# S1C31D50 register map
Vendor: Epson; Series: S1C31D50; File version: 1.00
CPU: CM0PLUS r0p1, little endian, MPU, no FPU, VTOR, 2 interrupt priority bits
Registers are 16-bit, read-write, reset 0x0 unless marked. A register's access mark holds for its fields unless they carry their own. Offsets are from the block's base; [hi:lo] are bit positions; {n}, {i} and the like mark numbered series; 'fields as' and 'values as' point back to an identical list.

## SDAC_0 — SOUND DAC
Base 0x00200860
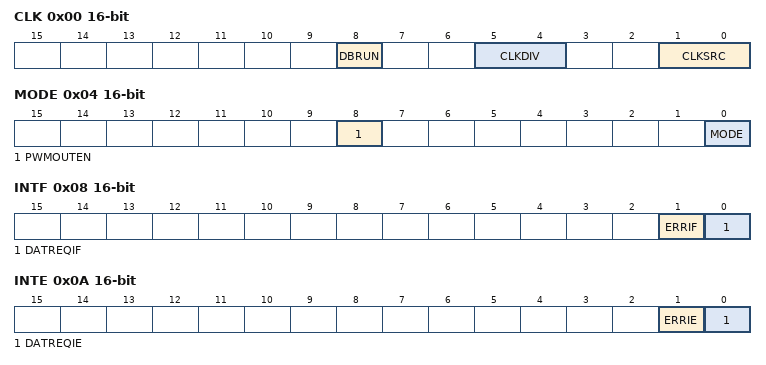
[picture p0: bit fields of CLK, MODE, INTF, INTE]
0x00 CLK — Clock Control Register
  [8] DBRUN — RUN
    0=STOP (Timer is stopped and does not operate); 1=RUN (Timer is started and operates)
  [5:4] CLKDIV — Clock division ratio
  [1:0] CLKSRC — Clock source select
    3=EXOSC (External OSC); 2=OSC3; 0=IOSC
0x02 CTL — SDAC Control Register
  [0] SDACEN — Enable SDAC operation
    1=ENABLE (SDAC Enable); 0=DISABLE (SDAC Disable)
0x04 MODE — SDAC mode select Register
  [8] PWMOUTEN — Enable PWM Output
    1=ENABLE (PWM Output Enable); 0=DISABLE (PWM Output Diable)
  [0] MODE — SDAC mode select
    1=BUZZ (Buzz mode); 0=STANDARD (Standard mode)
0x06 DAT — SDAC Data Register
  [9:0] DAT — SDAC Data
0x08 INTF — Interrupt Flag Register
  [1] ERRIF write-1-clears — ERROR occured interrupt flag
    0=NOT_OCCURED (No cause of interrupt occurred); 1=OCCURED (Cause of interrupt occurred)
  [0] DATREQIF write-1-clears — SDAC DATA request interrupt flag
    values as ERRIF
0x0A INTE — Interrupt Enable Register
  [1] ERRIE — ERROR occued interrupt enable
    0=DISABLE; 1=ENABLE
  [0] DATREQIE — SDAC DATA request interrupt enable
    0=DISABLE; 1=ENABLE
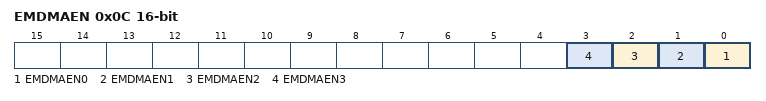
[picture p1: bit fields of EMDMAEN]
0x0C EMDMAEN — SDAC Buffer Empty DMA Request Enable Register
  [all] fields
    0=DISABLE; 1=ENABLE
  [n] EMDMAEN{n} (n=0..3) — Buffer Empty DMA ch{n} request enable

## HWPROC — HW Processor
Base 0x002008A0
0x02 CTL — HW Processor Control Register
  [0] HWPEN — HW Processor Enable
    0=DISABLE (SOUND Disabled (clock is stopped)); 1=ENABLE (SOUND Enabled (clock is supplied))
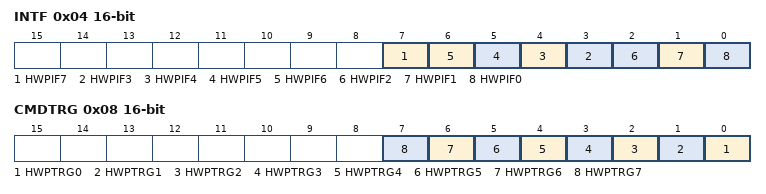
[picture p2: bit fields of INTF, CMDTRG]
0x04 INTF — HW Processor Interrupt Flag Register
  [all] fields
    on write: 0=CLEAR (Clears the interrupt flag); 1=PROHIBITED (Setting prohibited); 0=NOT_OCCURED (No cause of interrupt occurred); 1=OCCURED (Cause of interrupt occurred)
  [7] HWPIF7 — HW Processor interrupt flag 7(DBGIF)
  [n] HWPIF{n} (n=3..6) — HW Processor interrupt flag {n}
  [2] HWPIF2 — HW Processor Interrupt Flag 2
  [1] HWPIF1 — HW Processor interrupt flag 1(ERRIF)
  [0] HWPIF0 — HW Processor interrupt flag 0(STIF)
0x06 INTE — HW Processor Interrupt Enable Register
  [0] HWPIE — HW Processor interrupt enable
    0=DISABLE; 1=ENABLE
0x08 CMDTRG — HW Processor Start Trigger Register
  [all] fields
    on write: 0=PROHIBITED (Setting prohibited); 1=SET (Sets the command trigger); 0=READY (Ready to set the command trigger); 1=IN_PROGRESS (Setting in progress)
  [n] HWPTRG{n} (n=0..7) — HW Processor command trirgger {n}
0x0A C2HINTE — CPU Core to HW Processor Interrupt Enable Register
  [0] C2HIE — CPU Core to HW Processor interrupt enable
    0=DISABLE; 1=ENABLE

## WDT2 — Watchdog 2 timer counter, clock source and clock division ratio control
Base 0x002000A0
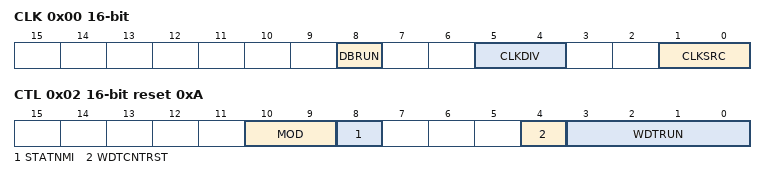
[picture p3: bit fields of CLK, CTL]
0x00 CLK — WDT Clock Control Register
  [8] DBRUN — Enable clock on debug mode (can be write protected)
    0=DISABLE; 1=ENABLE
  [5:4] CLKDIV — Clock division select (can be write protected)
  [1:0] CLKSRC — Clock source select (can be write protected)
    0=IOSC; 1=OSC1; 2=OSC3; 3=EXOSC
0x02 CTL reset 0xA — Control Register
  [10:9] MOD — WDT2 operating mode (can be write protected)
    0=RESET (Reset mode); 1=NMI (NMI mode); 2=RESET_AFTER_NMI (Reset after NMI mode)
  [8] STATNMI ro — Counter overflow and NMI status
    0=NO_NMI (NMI not occurred); 1=NMI (NMI (counter overflow) occurred)
  [4] WDTCNTRST — WDT2 counter reset (can be write protected)
    0=IGNORED; 1=RESET
  [3:0] WDTRUN — WDT2 run and stop control (can be write protected)
    10=STOP
0x04 CMP reset 0x3FF — Counter Compare Match Register
  [9:0] CMP — WDT2 Compare Match (can be write protected)

## HWPCOMMON — HW Processor Common Function
Base 0x00156700; alternate view of MEMCHECK
0x00 FUNCTION — HW Processor Common Function Register
  [7:0] ID — Function ID
    0=SOUND_PLAY; 3=MEM_CHECK (memory check)
0x44 ERROR — HW Processor Common Error Register
  [15:0] ERROR ro
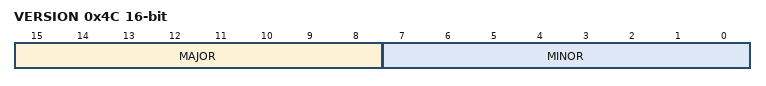
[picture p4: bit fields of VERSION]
0x4C VERSION — HW Processor Common Version Register
  [15:8] MAJOR ro — Major Version
  [7:0] MINOR ro — Minor Version
0x50 FRAMES 32-bit — HW Processor Common Frame Counter Register
  [31:0] FRAMES ro — Frame Counter

## SOUNDPLAY — Sound Play Fucntion
Base 0x00156700; alternate view of MEMCHECK
0x00 FUNCTION — Sound Play Function Register
  [7:0] ID — Function ID
    0=SOUND_PLAY; 3=MEM_CHECK (memory check)
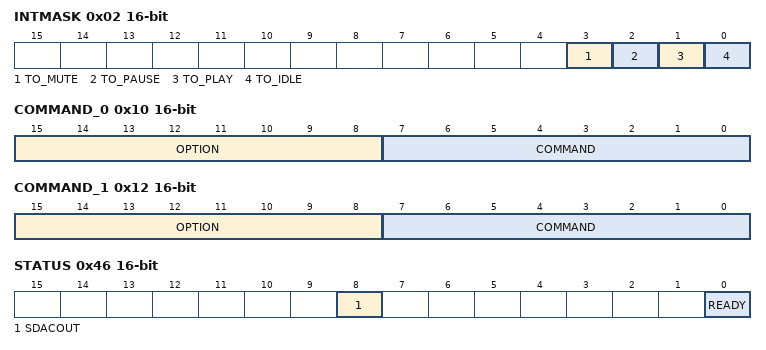
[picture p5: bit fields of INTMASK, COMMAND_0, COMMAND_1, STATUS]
0x02 INTMASK — Sound Play Interrupt Causes Mask Register
  [all] fields
    1=Enable (mask enable); 0=Disable (mask disable)
  [3] TO_MUTE — trainsion to mute
  [2] TO_PAUSE — trainsion to pause
  [1] TO_PLAY — trainsion to play
  [0] TO_IDLE — trainsion to idle
0x04 ROMADDR 32-bit — Sound Play ROM Start Address Register
  [31:0] ADDRESS
0x08 ROMSIZE 32-bit — Sound Play ROM Size Register
  [31:0] SIZE
0x0C KEYCODE 32-bit — Sound Play KEYYCODE Register
0x10 COMMAND_0 — Sound Play Command Register Ch.0
  [15:8] OPTION, [7:0] COMMAND
0x12 COMMAND_1 — Sound Play Command Register Ch.1
  [15:8] OPTION, [7:0] COMMAND
0x14 SENTENCE_0 — Sound Play Sentence No. Register Ch.0
  [15:0] SENTENCE_NO — Sentence Number
0x16 SENTENCE_1 — Sound Play Sentence No. Register Ch.1
  [15:0] SENTENCE_NO — Sentence Number
0x18 VOLUME_0 — Sound Play Volume Register Ch.0
  [6:0] VOLUME
0x1A VOLUME_1 — Sound Play Volume Register Ch.1
  [6:0] VOLUME
0x1C REPEAT_0 — Sound Play Repeat Register Ch.0
  [7:0] REPEAT
0x1E REPEAT_1 — Sound Play Repeat Register Ch.1
  [7:0] REPEAT
0x20 SPEED_0 — Sound Play Speed Register Ch.0
  [7:0] SPEED
0x28 PCMADDR 32-bit — Sound Play PCM Data Start Address Register
  [31:0] ADDRESS
0x2C PCMSIZE 32-bit — Sound Play PCM Data Size Register
  [31:0] SIZE
0x40 STATE_0 — Sound Play State Register Ch.0
  [15:0] STATE
    0=vp_state_idle; 1=vp_state_play; 2=vp_state_pause; 3=vp_state_mute; 4=vp_state_play_fadeout; 5=vp_state_play_bufout; 6=vp_state_play_dacout; 7=vp_state_play_fadein
0x42 STATE_1 — Sound Play State Register Ch.1
  fields as STATE_0
0x44 ERROR — Sound Play Error Register
0x46 STATUS — Sound Play Status Register
  [8] SDACOUT — SDAC output flag
    0=ON (On processing); 1=OFF (Not on processing)
  [0] READY — Ready Flag
    0=READY; 1=NOT_READY
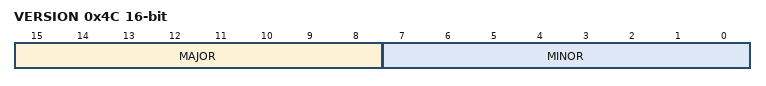
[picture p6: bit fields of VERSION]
0x4C VERSION — Sound Play Version Register
  [15:8] MAJOR — Major Version
  [7:0] MINOR — Minor Version

## MEMCHECK — Memory Check Function
Base 0x00156700; alternate view of HWPCOMMON
0x00 FUNCTION — Memory Check Function Register
  [7:0] ID — Function ID
    0=SOUND_PLAY; 3=MEM_CHECK (memory check)
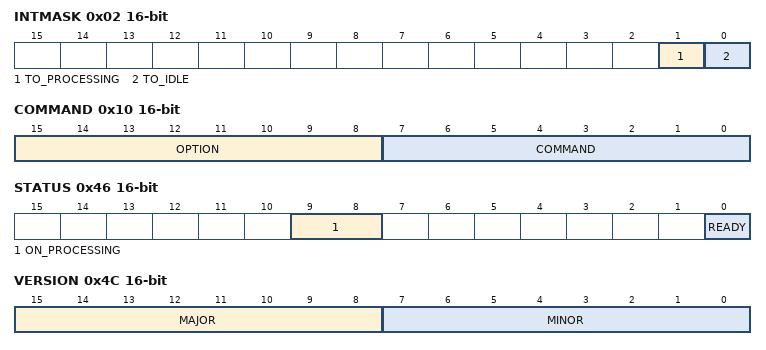
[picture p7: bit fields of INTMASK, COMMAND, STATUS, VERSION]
0x02 INTMASK — Memory Check Interrupt Causes Mask Register
  [1] TO_PROCESSING — trainsion to processing
    1=Enable (mask enable); 0=Disable (mask disable)
  [0] TO_IDLE — trainsion to idle
    1=Enable (mask enable); 0=Disable (mask disable)
0x04 MEMADDR 32-bit — Memory Check Memory Start Address Register
  [31:0] ADDRESS
0x08 MEMSIZE 32-bit — Memory Check Memory Size Register
  [31:0] SIZE
0x0C INITVALUE 32-bit — Memory Check Intialization Value Register
  [31:0] INITVALUE — Initialization Value
0x10 COMMAND — Memory Check Command Register
  [15:8] OPTION, [7:0] COMMAND
0x40 STATE — Memory Check State Register
  [15:0] STATE
    0=mc_state_idle; 1=mc_state_ram_check; 2=mc_state_ram_check_by_march_c; 3=mc_state_flash_checksum; 4=mc_state_flash_crc
0x44 ERROR — Memory Check Error Register
  [15:0] ERROR
    0=ERR_NO_ERROR (No Error); 1=ERR_COMMAND (Command error); 0x8000=ERR_FUNCTION_ID (Function ID error)
0x46 STATUS — Memory Check Status Register
  [9:8] ON_PROCESSING — On Processing Flag
    0=ON_PROCESSING; 1=NOT_ON_PROCESSING
  [0] READY — Ready Flag
    0=READY; 1=NOT_READY
0x48 RESULT 32-bit — Memory Check Result Register
0x4C VERSION — Memor Check Version Register
  [15:8] MAJOR — Major Version
  [7:0] MINOR — Minor Version
